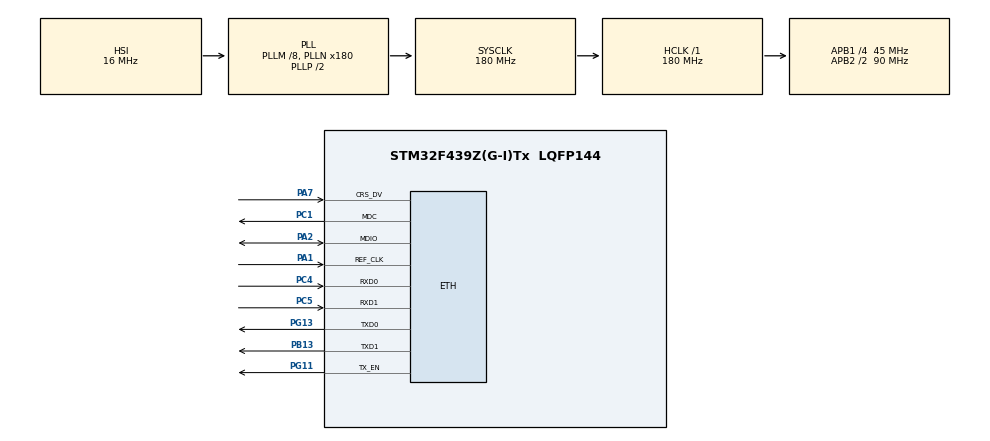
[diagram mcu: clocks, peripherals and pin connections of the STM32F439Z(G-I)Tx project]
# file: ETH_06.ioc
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ETH.MediaInterface=HAL_ETH_RMII_MODE
FREERTOS.Tasks01=TaskTCP,24,128,StartDefaultTask,Default,NULL,Dynamic,NULL,NULL;TaskUDP,8,128,StartTask02,Default,NULL,Dynamic,NULL,NULL
FREERTOS.configCHECK_FOR_STACK_OVERFLOW=2
FREERTOS.configENABLE_FPU=1
FREERTOS.configTOTAL_HEAP_SIZE=32768
FREERTOS.configUSE_NEWLIB_REENTRANT=1
LWIP.BSP.number=1
LWIP.GATEWAY_ADDRESS=192.168.000.000
LWIP.IP_ADDRESS=192.168.000.123
LWIP.LWIP_DHCP=0
LWIP.LWIP_SO_RCVBUF=1
LWIP.NETMASK_ADDRESS=255.255.255.000
LWIP.Version=v2.1.2_Cube
LWIP0.BSP.STBoard=false
LWIP0.BSP.api=BSP_COMPONENT_DRIVER
LWIP0.BSP.component=LAN8742
LWIP0.BSP.instance=LAN8742
LWIP0.BSP.name=Driver_PHY
LWIP0.BSP.semaphore=S_LAN8742
LWIP0.BSP.solution=LAN8742
Mcu.Family=STM32F4
Mcu.Name=STM32F439Z(G-I)Tx
Mcu.Package=LQFP144
NVIC.ETH_IRQn=true\:5\:0\:false\:false\:true\:true\:true\:true\:true
NVIC.PriorityGroup=NVIC_PRIORITYGROUP_4
NVIC.TIM1_UP_TIM10_IRQn=true\:15\:0\:false\:false\:true\:false\:false\:true\:true
NVIC.TimeBase=TIM1_UP_TIM10_IRQn
NVIC.TimeBaseIP=TIM1
PA1.Mode=RMII
PA1.Signal=ETH_REF_CLK
PA2.Mode=RMII
PA2.Signal=ETH_MDIO
PA7.Mode=RMII
PA7.Signal=ETH_CRS_DV
PB13.Mode=RMII
PB13.Signal=ETH_TXD1
PC1.Mode=RMII
PC1.Signal=ETH_MDC
PC14/OSC32_IN.Mode=LSE-External-Oscillator
PC14/OSC32_IN.Signal=RCC_OSC32_IN
PC15/OSC32_OUT.Mode=LSE-External-Oscillator
PC15/OSC32_OUT.Signal=RCC_OSC32_OUT
PC4.Mode=RMII
PC4.Signal=ETH_RXD0
PC5.Mode=RMII
PC5.Signal=ETH_RXD1
PG11.Mode=RMII
PG11.Signal=ETH_TX_EN
PG13.Mode=RMII
PG13.Signal=ETH_TXD0
PH0/OSC_IN.Mode=HSE-External-Clock-Source
PH0/OSC_IN.Signal=RCC_OSC_IN
PH1/OSC_OUT.Mode=HSE-External-Clock-Source
PH1/OSC_OUT.Signal=RCC_OSC_OUT
ProjectManager.HeapSize=0x200
ProjectManager.StackSize=0x400
ProjectManager.TargetToolchain=STM32CubeIDE
RCC.48MHZClocksFreq_Value=90000000
RCC.AHBFreq_Value=180000000
RCC.APB1CLKDivider=RCC_HCLK_DIV4
RCC.APB1Freq_Value=45000000
RCC.APB1TimFreq_Value=90000000
RCC.APB2CLKDivider=RCC_HCLK_DIV2
RCC.APB2Freq_Value=90000000
RCC.APB2TimFreq_Value=180000000
RCC.CortexFreq_Value=180000000
RCC.HCLKFreq_Value=180000000
RCC.HSE_VALUE=25000000
RCC.HSI_VALUE=16000000
RCC.PLLM=15
RCC.PLLN=216
RCC.PLLSourceVirtual=RCC_PLLSOURCE_HSE
RCC.SYSCLKFreq_VALUE=180000000
RCC.SYSCLKSource=RCC_SYSCLKSOURCE_PLLCLK
RCC.VCOOutputFreq_Value=360000000
VP_FREERTOS_VS_CMSIS_V2.Mode=CMSIS_V2
VP_LWIP_VS_Enabled.Mode=Enabled
VP_SYS_VS_tim1.Mode=TIM1
board=custom

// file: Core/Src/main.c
/* USER CODE BEGIN Header */
/**
  ******************************************************************************
  * @file           : main.c
  * @brief          : Main program body
  ******************************************************************************
  * @attention
  *
  * Copyright (c) 2024 STMicroelectronics.
  * All rights reserved.
  *
  * This software is licensed under terms that can be found in the LICENSE file
  * in the root directory of this software component.
  * If no LICENSE file comes with this software, it is provided AS-IS.
  *
  ******************************************************************************
  */
/* USER CODE END Header */
#include "main.h"
#include "cmsis_os.h"
#include "lwip.h"

/* USER CODE BEGIN Includes */

#include "udpserver.h"
#include "tcpserver.h"
#include "lwip_mqtt.h"

/* USER CODE END Includes */

/* Definitions for TaskTCP */
osThreadId_t TaskTCPHandle;
const osThreadAttr_t TaskTCP_attributes = {
  .name = "TaskTCP",
  .stack_size = 128 * 8,
  .priority = (osPriority_t) osPriorityNormal,
};
/* Definitions for TaskUDP */
osThreadId_t TaskUDPHandle;
const osThreadAttr_t TaskUDP_attributes = {
  .name = "TaskUDP",
  .stack_size = 128 * 16,
  .priority = (osPriority_t) osPriorityLow,
};

void SystemClock_Config(void);
static void MX_GPIO_Init(void);
void StartDefaultTask(void *argument);
void StartTask02(void *argument);

/* USER CODE BEGIN 0 */

extern struct netif gnetif;
/* USER CODE END 0 */

int main(void)
{

  /* MCU Configuration--------------------------------------------------------*/

  /* Reset of all peripherals, Initializes the Flash interface and the Systick. */
  HAL_Init();

  /* Configure the system clock */
  SystemClock_Config();

  /* Initialize all configured peripherals */
  MX_GPIO_Init();
  /* USER CODE BEGIN 2 */

  //udpServer_init();
  //tcp_server_init();

  /* USER CODE END 2 */

  /* Init scheduler */
  osKernelInitialize();

  /* Create the thread(s) */
  /* creation of TaskTCP */
  TaskTCPHandle = osThreadNew(StartDefaultTask, NULL, &TaskTCP_attributes);

  /* creation of TaskUDP */
  TaskUDPHandle = osThreadNew(StartTask02, NULL, &TaskUDP_attributes);

  /* Start scheduler */
  osKernelStart();

  /* We should never get here as control is now taken by the scheduler */
  /* Infinite loop */
  while (1)
  {

    /* USER CODE BEGIN 3 */
	  //ethernetif_input(&gnetif);

	  //sys_check_timeouts();
  }
  /* USER CODE END 3 */
}

void SystemClock_Config(void)
{
  RCC_OscInitTypeDef RCC_OscInitStruct = {0};
  RCC_ClkInitTypeDef RCC_ClkInitStruct = {0};

  /** Configure the main internal regulator output voltage
  */
  __HAL_RCC_PWR_CLK_ENABLE();
  __HAL_PWR_VOLTAGESCALING_CONFIG(PWR_REGULATOR_VOLTAGE_SCALE1);

  /** Initializes the RCC Oscillators according to the specified parameters
  * in the RCC_OscInitTypeDef structure.
  */
  RCC_OscInitStruct.OscillatorType = RCC_OSCILLATORTYPE_HSI;
  RCC_OscInitStruct.HSIState = RCC_HSI_ON;
  RCC_OscInitStruct.HSICalibrationValue = RCC_HSICALIBRATION_DEFAULT;
  RCC_OscInitStruct.PLL.PLLState = RCC_PLL_ON;
  RCC_OscInitStruct.PLL.PLLSource = RCC_PLLSOURCE_HSI;
  RCC_OscInitStruct.PLL.PLLM = 8;
  RCC_OscInitStruct.PLL.PLLN = 180;
  RCC_OscInitStruct.PLL.PLLP = RCC_PLLP_DIV2;
  RCC_OscInitStruct.PLL.PLLQ = 4;
  if (HAL_RCC_OscConfig(&RCC_OscInitStruct) != HAL_OK)
  {
    Error_Handler();
  }

  /** Activate the Over-Drive mode
  */
  if (HAL_PWREx_EnableOverDrive() != HAL_OK)
  {
    Error_Handler();
  }

  /** Initializes the CPU, AHB and APB buses clocks
  */
  RCC_ClkInitStruct.ClockType = RCC_CLOCKTYPE_HCLK|RCC_CLOCKTYPE_SYSCLK
                              |RCC_CLOCKTYPE_PCLK1|RCC_CLOCKTYPE_PCLK2;
  RCC_ClkInitStruct.SYSCLKSource = RCC_SYSCLKSOURCE_PLLCLK;
  RCC_ClkInitStruct.AHBCLKDivider = RCC_SYSCLK_DIV1;
  RCC_ClkInitStruct.APB1CLKDivider = RCC_HCLK_DIV4;
  RCC_ClkInitStruct.APB2CLKDivider = RCC_HCLK_DIV2;

  if (HAL_RCC_ClockConfig(&RCC_ClkInitStruct, FLASH_LATENCY_5) != HAL_OK)
  {
    Error_Handler();
  }
}

static void MX_GPIO_Init(void)
{

  /* GPIO Ports Clock Enable */
  __HAL_RCC_GPIOH_CLK_ENABLE();
  __HAL_RCC_GPIOC_CLK_ENABLE();
  __HAL_RCC_GPIOA_CLK_ENABLE();
  __HAL_RCC_GPIOB_CLK_ENABLE();
  __HAL_RCC_GPIOG_CLK_ENABLE();

}

/* USER CODE BEGIN 4 */

mqtt_client_t *client;
char pacote[1000];

/* USER CODE END 4 */

void StartDefaultTask(void *argument)
{
  /* init code for LWIP */
  MX_LWIP_Init();
  /* USER CODE BEGIN 5 */
  tcpserver_init();

  //client = mqtt_client_new();

  /* Infinite loop */
  for(;;)
  {

	  /*
	  if(client != NULL) {
	sprintf(pacote,"hello_mohamed");
	    example_do_connect(client, "hello_world");
	    example_publish(client, pacote);
	  }
	   */
	  //tcpserver_init();
    osDelay(500);

  }
  /* USER CODE END 5 */
}

void StartTask02(void *argument)
{
  /* USER CODE BEGIN StartTask02 */
  udpserver_init();

  /* Infinite loop */
  for(;;)
  {
    osDelay(1);
  }
  /* USER CODE END StartTask02 */
}

void HAL_TIM_PeriodElapsedCallback(TIM_HandleTypeDef *htim)
{
  if (htim->Instance == TIM1) {
    HAL_IncTick();
  }
}

void Error_Handler(void)
{
  __disable_irq();
  while (1)
  {
  }
}
